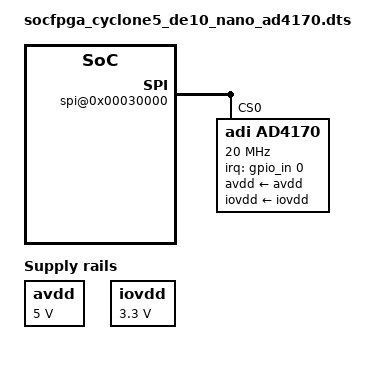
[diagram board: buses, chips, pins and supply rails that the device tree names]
// SPDX-License-Identifier: GPL-2.0
/*
 * Analog Devices CN0540
 * https://www.analog.com/en/design-center/reference-designs/circuits-from-the-lab/cn0540.html
 * https://www.analog.com/en/products/ad4170.html
 * https://wiki.analog.com/resources/tools-software/linux-build/generic/socfpga
 *
 * hdl_project: <cn0540/de10nano>
 * board_revision: <A>
 *
 * Copyright (C) 2024 Analog Devices Inc.
 */
/dts-v1/;
#include "socfpga_cyclone5_de10_nano_hps_pio21.dtsi"
#include <dt-bindings/interrupt-controller/irq.h>
#include <dt-bindings/iio/adc/adi,ad4170.h>

/ {
	avdd: avdd-regulator {
		compatible = "regulator-fixed";
		regulator-name = "Eval AVDD supply";
		regulator-min-microvolt = <5000000>;
		regulator-max-microvolt = <5000000>;
		regulator-boot-on;
	};
	iovdd: iovdd-regulator {
		compatible = "regulator-fixed";
		regulator-name = "Eval IOVDD supply";
		regulator-min-microvolt = <3300000>;
		regulator-max-microvolt = <3300000>;
		regulator-boot-on;
	};
};

&fpga_axi {
	axi_dmac_0: rx-dma@0x00020000 {
		compatible = "adi,axi-dmac-1.00.a";
		reg = <0x00020000 0x00000800>;
		interrupt-parent = <&intc>;
		interrupts = <0 44 IRQ_TYPE_LEVEL_HIGH>;
		#dma-cells = <1>;
		clocks = <&h2f_user0_clk>;

		adi,channels {
			#size-cells = <0>;
			#address-cells = <1>;

			dma-channel@0 {
				reg = <0>;
				adi,source-bus-width = <32>;
				adi,source-bus-type = <1>;
				adi,destination-bus-width = <64>;
				adi,destination-bus-type = <0>;
			};
		};
	};

	spi@0x00030000 {
		compatible = "adi-ex,axi-spi-engine-1.00.a";
		reg = <0x00030000 0x00010000>;
		interrupt-parent = <&intc>;
		interrupts = <0 45 IRQ_TYPE_LEVEL_HIGH>;
		clocks = <&sys_clk &h2f_user0_clk>;
		clock-names = "s_axi_aclk", "spi_clk";
		num-cs = <1>;
		#address-cells = <0x1>;
		#size-cells = <0x0>;

		ad4170@0 {
			compatible = "adi,ad4170";
			reg = <0>;
			spi-max-frequency = <20000000>;
			spi-cpol;
			spi-cpha;
			avdd-supply = <&avdd>;
			iovdd-supply = <&iovdd>;
			interrupt-parent = <&gpio_in>;
			interrupts = <0 IRQ_TYPE_EDGE_FALLING>;
			dmas = <&axi_dmac_0 0>;
			dma-names = "rx";
			adi,dig-aux1 = /bits/ 8 <1>;
			adi,dig-aux2 = /bits/ 8 <0>;
			adi,sync-option = /bits/ 8 <0>;
			#address-cells = <1>;
			#size-cells = <0>;

			/*
			 * Sample AIN0 with respect to AIN1 throughout AVDD/AVSS
			 * input range. Fully differential.
			 * If AVSS < 0V, Fully differential true bipolar.
			 */
			channel@0 {
				reg = <0>;
				bipolar;
				diff-channels = <AD4170_MAP_AIN0 AD4170_MAP_AIN1>;
				adi,reference-select = /bits/ 8 <3>;
			};
			/*
			 * Sample AIN8 with respect to DGND throughout
			 * REFOUT/AVSS input range
			 * Pseudo-differential unipolar
			 */
			channel@8 {
				reg = <8>;
				diff-channels = <AD4170_MAP_AIN8 AD4170_MAP_DGND>;
				adi,reference-select = /bits/ 8 <2>;
			};
			/* Temperature sensor */
			channel@1 {
				reg = <1>;
				bipolar;
				diff-channels = <AD4170_MAP_TEMP_SENSOR_P
						 AD4170_MAP_TEMP_SENSOR_N>;
				adi,reference-select = /bits/ 8 <2>;
			};
		};
	};
};
